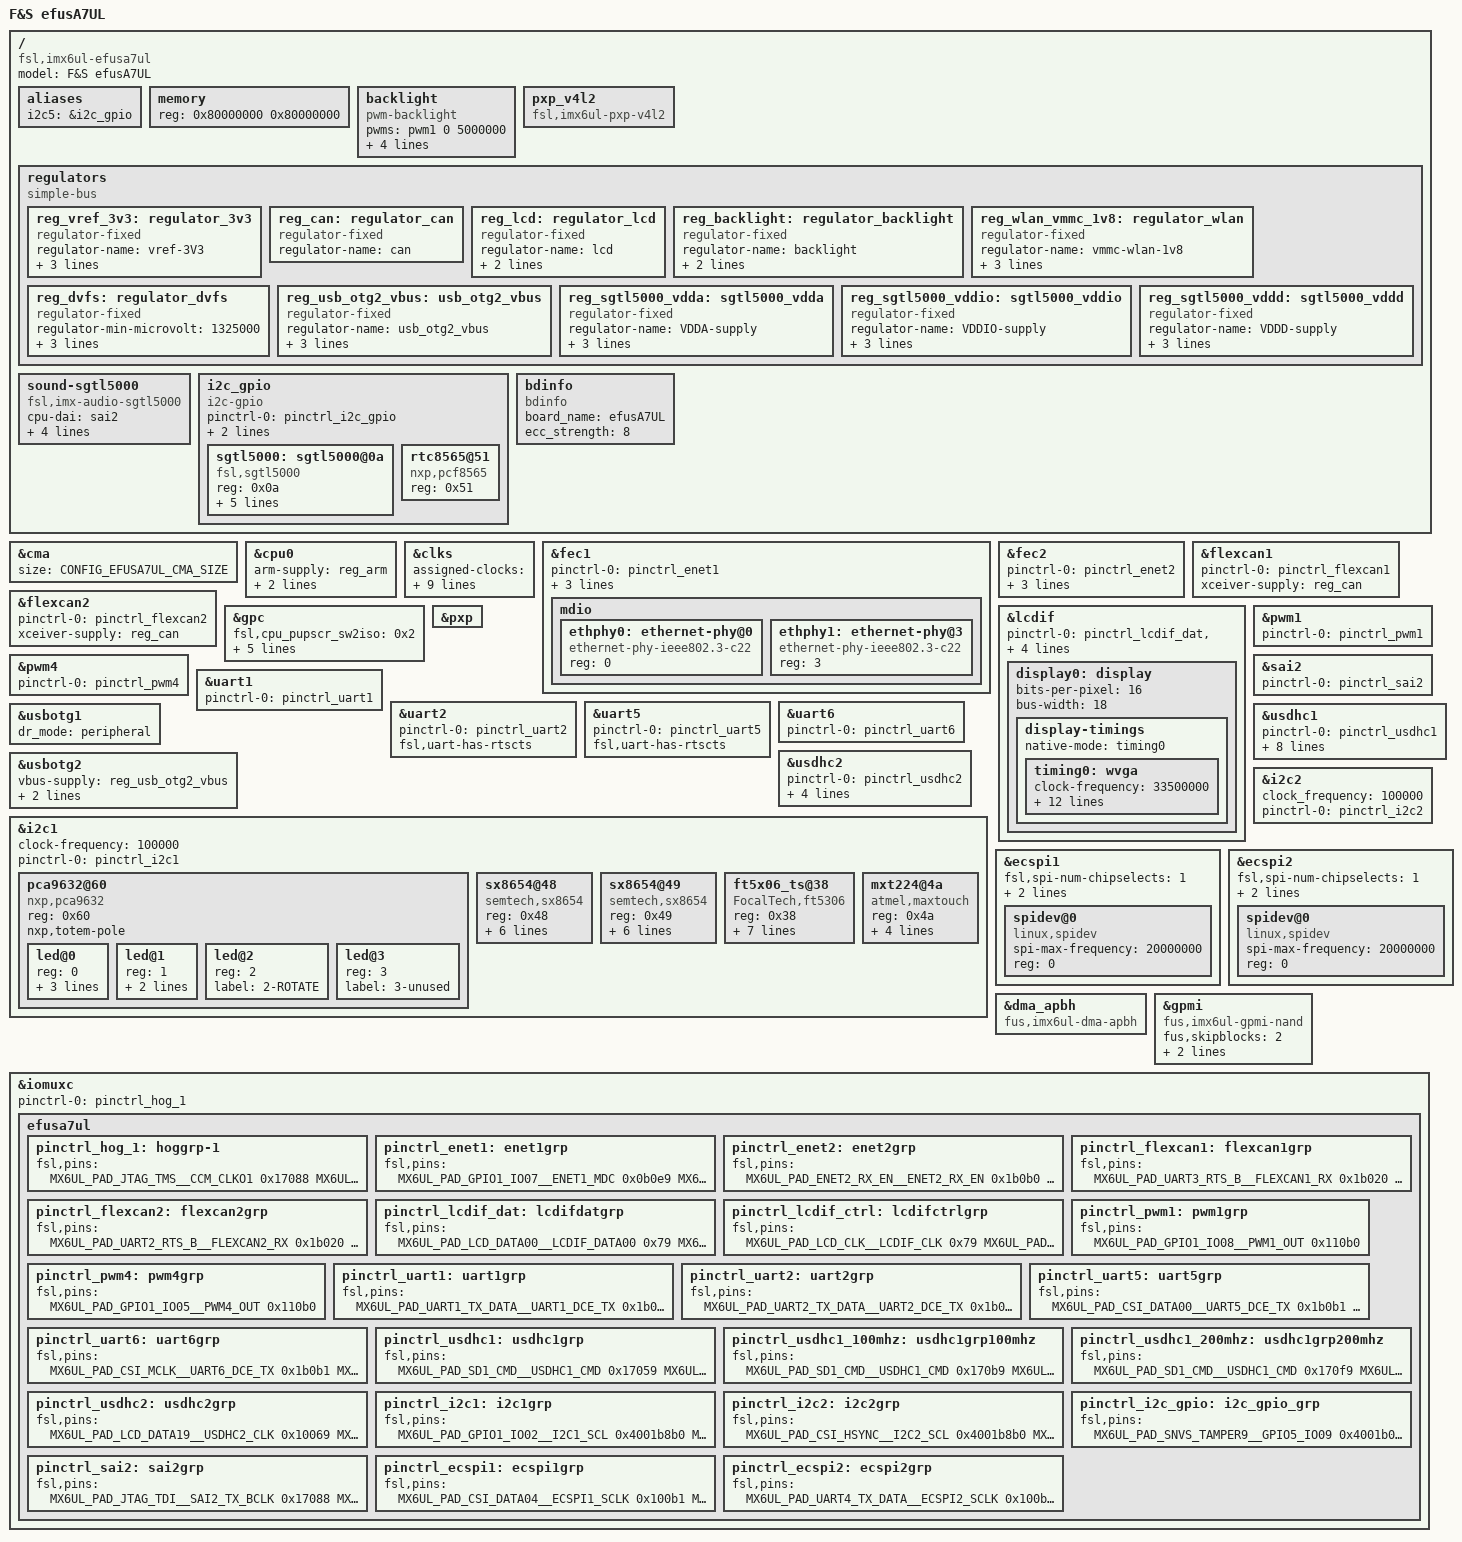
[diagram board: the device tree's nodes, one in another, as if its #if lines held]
/*
 * Copyright (C) 2015 Freescale Semiconductor, Inc.
 *
 * This program is free software; you can redistribute it and/or modify
 * it under the terms of the GNU General Public License version 2 as
 * published by the Free Software Foundation.
 */

#define CONFIG_EFUSA7UL_WLAN
#define CONFIG_EFUSA7UL_NAND
//#define CONFIG_EFUSA7UL_SD_A_CDWP

/* Please select only one of the following touch devices. Make sure that the
   corresponding touchscreen driver is activated in the kernel */
//#define CONFIG_EFUSA7UL_4WTOUCH_SX8655_ONBOARD
#define CONFIG_EFUSA7UL_4WTOUCH_SX8655_RGBADAPTER
//#define CONFIG_EFUSA7UL_CAPTOUCH_MXT224
//#define CONFIG_EFUSA7UL_CAPTOUCH_FT5x06

/* CMA: Set 64 MB for Continuous Memory Allocator */
#define CONFIG_EFUSA7UL_CMA_SIZE 0x4000000


/dts-v1/;

#include <dt-bindings/input/input.h>
#include "imx6ul.dtsi"

/ {
	model = "F&S efusA7UL";
	compatible = "fsl,imx6ul-efusa7ul", "fsl,imx6ul";

	aliases {
		i2c5 = &i2c_gpio;
	};
#if 0
	chosen {
		stdout-path = &uart1;
	};
#endif

	memory {
		reg = <0x80000000 0x80000000>;
	};

	backlight {
		compatible = "pwm-backlight";
		pwms = <&pwm1 0 5000000>;
		brightness-levels = <0 1 5 10 18 28 41 56
				     73 92 113 137 163 192 222 255>;
		default-brightness-level = <14>;
		power-supply = <&reg_backlight>;
		status = "okay";
	};

	pxp_v4l2 {
		compatible = "fsl,imx6ul-pxp-v4l2", "fsl,imx6sx-pxp-v4l2", "fsl,imx6sl-pxp-v4l2";
		status = "okay";
	};

	regulators {
		compatible = "simple-bus";
		#address-cells = <1>;
		#size-cells = <0>;

		reg_vref_3v3: regulator_3v3 {
			compatible = "regulator-fixed";
			regulator-name = "vref-3V3";
			regulator-min-microvolt = <3300000>;
			regulator-max-microvolt = <3300000>;
			regulator-always-on;
		};

		reg_can: regulator_can {
			compatible = "regulator-fixed";
			regulator-name = "can";
		};

		reg_lcd: regulator_lcd {
			compatible = "regulator-fixed";
			regulator-name = "lcd";
			gpio = <&gpio5 4 0>;
			enable-active-high;
		};

		reg_backlight: regulator_backlight {
			compatible = "regulator-fixed";
			regulator-name = "backlight";
			gpio = <&gpio5 5 0>;
			enable-active-high;
		};

#ifdef CONFIG_EFUSA7UL_WLAN
		reg_wlan_vmmc_1v8: regulator_wlan {
			compatible = "regulator-fixed";
			regulator-name = "vmmc-wlan-1v8";
			regulator-min-microvolt = <1800000>;
			regulator-max-microvolt = <1800000>;
			regulator-always-on;
		};
#endif

		reg_dvfs: regulator_dvfs {
			compatible = "regulator-fixed";
			regulator-min-microvolt = <1325000>;
			regulator-max-microvolt = <1325000>;
			regulator-name = "dvfs";
			regulator-always-on;
		};

		reg_usb_otg2_vbus: usb_otg2_vbus {
			compatible = "regulator-fixed";
			regulator-name = "usb_otg2_vbus";
			regulator-min-microvolt = <5000000>;
			regulator-max-microvolt = <5000000>;
			regulator-always-on;
		};

		/* SGTL5000 analog voltage */
		reg_sgtl5000_vdda: sgtl5000_vdda {
			compatible = "regulator-fixed";
			regulator-name = "VDDA-supply";
			regulator-min-microvolt = <3000000>;
			regulator-max-microvolt = <3000000>;
			regulator-always-on;
		};

		/* SGTL5000 I/O voltage */
		reg_sgtl5000_vddio: sgtl5000_vddio {
			compatible = "regulator-fixed";
			regulator-name = "VDDIO-supply";
			regulator-min-microvolt = <3300000>;
			regulator-max-microvolt = <3300000>;
			regulator-always-on;
		};

		/* SGTL5000 internal digital voltage */
		reg_sgtl5000_vddd: sgtl5000_vddd {
			compatible = "regulator-fixed";
			regulator-name = "VDDD-supply";
			regulator-min-microvolt = <1500000>;
			regulator-max-microvolt = <1500000>;
			regulator-always-on;
		};
	};

#if 1 //###
	sound-sgtl5000 {
		compatible = "fsl,imx-audio-sgtl5000";
		cpu-dai = <&sai2>;
		audio-codec = <&sgtl5000>;
		model = "imx-sgtl5000";
		audio-routing =
			"LINE_IN", "Line In Jack",
//###			"MIC_IN", "Mic Jack",
//###			"Line Out Jack", "LINE_OUT",
			"Headphone Jack", "HP_OUT";
	};
#endif

	/* Bitbanging I2C */
	i2c_gpio: i2c_gpio {
		pinctrl-names = "default";
		pinctrl-0 = <&pinctrl_i2c_gpio>;
		compatible = "i2c-gpio";
		gpios = <&gpio5 8 0 /* sda */
			 &gpio5 9 0 /* scl */
			>;
//###		i2c-gpio,sda-open-drain;
//###		i2c-gpio,scl-open-drain;
		i2c-gpio,delay-us = <2>;	/* ~100 kHz */
		#address-cells = <1>;
		#size-cells = <0>;
	};

	/* -------------------- BOARD INFO -------------------- */
	bdinfo {
		compatible = "bdinfo";
		board_name = "efusA7UL";
		ecc_strength = "8";
	};
};

/* RAM size for Continues Memory Allocator */
&cma {
	size = <CONFIG_EFUSA7UL_CMA_SIZE>;
};

&cpu0 {
	arm-supply = <&reg_arm>;
	soc-supply = <&reg_soc>;
	dc-supply = <&reg_dvfs>;
};

&clks {
	assigned-clocks = <&clks IMX6UL_CLK_PLL4_AUDIO_DIV>,
			  <&clks IMX6UL_CLK_SAI2_SEL>,
			  <&clks IMX6UL_CLK_SAI2>,
			  <&clks IMX6UL_CLK_CKO2_SEL>,
			  <&clks IMX6UL_CLK_CKO>;

	assigned-clock-parents = <0>,
				 <&clks IMX6UL_CLK_PLL4_AUDIO_DIV>,
				 <0>,
				 <&clks IMX6UL_CLK_SAI2>,
				 <&clks IMX6UL_CLK_CKO2>;
//###	assigned-clock-rates = <786432000>, <0>, <24576000>;
	assigned-clock-rates = <786432000>, <0>, <12288000>;
};

&fec1 {
	pinctrl-names = "default";
	pinctrl-0 = <&pinctrl_enet1>;
	phy-mode = "rmii";
	phy-handle = <&ethphy0>;
	fsl,ref-clock-out;
	status = "okay";

	mdio {
		#address-cells = <1>;
		#size-cells = <0>;

		ethphy0: ethernet-phy@0 {
			compatible = "ethernet-phy-ieee802.3-c22";
			reg = <0>;
		};

		ethphy1: ethernet-phy@3 {
			compatible = "ethernet-phy-ieee802.3-c22";
			reg = <3>;
		};
	};
};

&fec2 {
	pinctrl-names = "default";
	pinctrl-0 = <&pinctrl_enet2>;
	phy-mode = "rmii";
	phy-handle = <&ethphy1>;
	fsl,ref-clock-out;
//###	status = "okay";
};

&flexcan1 {
	pinctrl-names = "default";
	pinctrl-0 = <&pinctrl_flexcan1>;
	xceiver-supply = <&reg_can>;
	status = "okay";
};

&flexcan2 {
	pinctrl-names = "default";
	pinctrl-0 = <&pinctrl_flexcan2>;
	xceiver-supply = <&reg_can>;
	status = "okay";
};

&gpc {
	fsl,cpu_pupscr_sw2iso = <0x2>;
	fsl,cpu_pupscr_sw = <0x1>;
	fsl,cpu_pdnscr_iso2sw = <0x1>;
	fsl,cpu_pdnscr_iso = <0x1>;
	fsl,wdog-reset = <1>; /* watchdog select of reset source */
	fsl,ldo-bypass = <0>; /* DCDC, ldo-enable */
};

&lcdif {
	pinctrl-names = "default";
	pinctrl-0 = <&pinctrl_lcdif_dat
		     &pinctrl_lcdif_ctrl>;
	lcd-supply = <&reg_lcd>;
	display = <&display0>;
	/* efusA7UL Rev 1.00 needs 5, later revisions need 0 */
	pattern = <5>;		/* RGB=0, RBG=1, GBR=2, GRB=3, BRG=4, BGR=5 */
	status = "okay";

	display0: display {
		bits-per-pixel = <16>;
		bus-width = <18>;

		display-timings {
			native-mode = <&timing0>;
			timing0: wvga {
				clock-frequency = <33500000>;
				hactive = <800>;
				vactive = <480>;
				hfront-porch = <40>;
				hback-porch = <88>;
				hsync-len = <128>;
				vback-porch = <33>;
				vfront-porch =<10>;
				vsync-len = <2>;
				hsync-active = <0>;
				vsync-active = <0>;
				de-active = <1>;
				pixelclk-active = <0>;
			};
		};
	};
};

&pwm1 {
	pinctrl-names = "default";
	pinctrl-0 = <&pinctrl_pwm1>;
	status = "okay";
};

&pwm4 {
	pinctrl-names = "default";
	pinctrl-0 = <&pinctrl_pwm4>;
	status = "okay";
};

&pxp {
	status = "okay";
};

&sai2 {
	pinctrl-names = "default";
	pinctrl-0 = <&pinctrl_sai2>;
#if 0 //### already assigned in &clks above
	assigned-clocks = <&clks IMX6UL_CLK_SAI2_SEL>,
			  <&clks IMX6UL_CLK_SAI2>;
	assigned-clock-parents = <&clks IMX6UL_CLK_PLL4_AUDIO_DIV>;
//###	assigned-clock-rates = <0>, <12288000>;
	assigned-clock-rates = <0>, <24576000>;
#endif
	status = "okay";
};

/* UART_A */
&uart1 {
	pinctrl-names = "default";
	pinctrl-0 = <&pinctrl_uart1>;
	status = "okay";
};

/* UART_B */
&uart2 {
	pinctrl-names = "default";
	pinctrl-0 = <&pinctrl_uart2>;
	fsl,uart-has-rtscts;
	status = "okay";
};

/* UART_C or UART for Bluetooth */
&uart5 {
	pinctrl-names = "default";
	pinctrl-0 = <&pinctrl_uart5>;
	fsl,uart-has-rtscts;
	status = "okay";
};

/* UART_D */
&uart6 {
	pinctrl-names = "default";
	pinctrl-0 = <&pinctrl_uart6>;
	status = "okay";
};

&usbotg1 {
	dr_mode = "peripheral";
	status = "okay";
};

&usbotg2 {
	vbus-supply = <&reg_usb_otg2_vbus>;
	dr_mode = "host";
	disable-over-current;
	status = "okay";
};

/* Either on-board WLAN or SD_A (Micro-SD slot on SKIT) */
&usdhc1 {
	pinctrl-names = "default", "state_100mhz", "state_200mhz";
	pinctrl-0 = <&pinctrl_usdhc1>;
	pinctrl-1 = <&pinctrl_usdhc1_100mhz>;
	pinctrl-2 = <&pinctrl_usdhc1_200mhz>;
	bus-width = <4>;
	vmmc-supply = <&reg_vref_3v3>;
#ifdef CONFIG_EFUSA7UL_WLAN
	non-removable;
	keep-power-in-suspend;
	enable-sdio-wakeup;
	vqmmc-supply = <&reg_wlan_vmmc_1v8>;
#else
#ifdef CONFIG_EFUSA7UL_SD_A_CDWP
	cd-gpios = <&gpio1 19 GPIO_ACTIVE_LOW>;
	wp-gpios = <&gpio1 18 0>;
#else
	non-removable;
#endif
#endif
	status = "okay";
};

/* Either on-board eMMC or SD_B (normal sized SD slot on SKIT) */
&usdhc2 {
	pinctrl-names = "default";
	pinctrl-0 = <&pinctrl_usdhc2>;
	no-1-8-v;
#ifdef CONFIG_EFUSA7UL_NAND
	/* Only 4 data lines for SD_B or eMMC available */
	bus-width = <4>;
#else
	/* Use 8 data lines for eMMC */
	bus-width = <8>;
#endif
	/* ### TODO: set non-removable only if eMMC or board rev 1.00;
	   actually U-Boot should overwrite this property at boot time */
#ifdef CONFIG_EFUSA7UL_SD_A_CDWP
	non-removable;
#else
	cd-gpios = <&gpio1 19 GPIO_ACTIVE_LOW>;
	wp-gpios = <&gpio1 18 0>;
#endif
	vmmc-supply = <&reg_vref_3v3>;
	status = "okay";
};

/* I2C_A: RGB-Connector (SKIT -> SX8655, LED-driver PCA9632), Touch Connector
   (SKIT -> FT5x06, MXT), SX8655 (SKIT), Feature Connector (SKIT) */
&i2c1 {
	clock-frequency = <100000>;
	pinctrl-names = "default";
	pinctrl-0 = <&pinctrl_i2c1>;
	status = "okay";

	pca9632@60 {
		compatible = "nxp,pca9632";
		reg = <0x60>;
		nxp,totem-pole;
		#address-cells = <1>;
		#size-cells = <0>;
		led@0 {
			reg = <0>;
			label = "0-PWRCTL";
			default-on;
			active-high;
		};
		led@1 {
			reg = <1>;
			label = "1-LEDCTRL";
			default-on;
		};
		led@2 {
			reg = <2>;
			label = "2-ROTATE";
		};
		led@3 {
			reg = <3>;
			label = "3-unused";
		};
	};

#ifdef CONFIG_EFUSA7UL_4WTOUCH_SX8655_ONBOARD
	/* 4/5 wire analog resistive touch, controller on efus SKIT */
	sx8654@48 {
		compatible = "semtech,sx8654";
		reg = <0x48>;
		touchrate = <0x30>;
		powdly = <0x06>;
		filt = <0x02>;
		setdly = <0x08>;
		pinctrl-names = "default";
		/*pinctrl-0 = <&pinctrl_touchscreen>;*/
		interrupt-parent = <&gpio5>;
		interrupts = <0 IRQ_TYPE_EDGE_FALLING>;
	};
#endif

#ifdef CONFIG_EFUSA7UL_4WTOUCH_SX8655_RGBADAPTER
	/* 4/5 wire analog resistive touch, controller on RGB adapter */
	sx8654@49 {
		compatible = "semtech,sx8654";
		reg = <0x49>;
		touchrate = <0x30>;
		powdly = <0x06>;
		filt = <0x02>;
		setdly = <0x08>;
		pinctrl-names = "default";
		/*pinctrl-0 = <&pinctrl_touchscreen>;*/
		interrupt-parent = <&gpio5>;
		interrupts = <0 IRQ_TYPE_EDGE_FALLING>;
	};
#endif

#ifdef CONFIG_EFUSA7UL_CAPTOUCH_FT5x06
	/* F&S driver V3.0 on Touch-Connector (I2C) */
	ft5x06_ts@38 {
		compatible = "FocalTech,ft5306";
		reg = <0x38>;
		fingers = <2>;
		touchscreen-size-x = <800>;
		touchscreen-size-y = <480>;
		threshold = <25>;
		interrupt-parent = <&gpio5>;
		interrupts = <0 IRQ_TYPE_EDGE_FALLING>;
		linux,wakeup;
	};
#endif

#ifdef CONFIG_EFUSA7UL_CAPTOUCH_MXT224
	/* Atmel PCAP touch on Touch-Connector (I2C) */
	mxt224@4a {
		compatible = "atmel,maxtouch";
		reg = <0x4a>;
		interrupt-parent = <&gpio5>;
		interrupts = <0 2>;
		atmel,cfg_name = "atmel/mxt224.cfg";
		atmel,reset-gpio = <&gpio5 2 GPIO_ACTIVE_LOW>;
#if 0
		atmel,suspend-mode = <2>;
		vdd = <&reg_atmel_mxt_vdd>;
		avdd = <&reg_atmel_mxt_avdd>;
#endif
	};
#endif
};

/* I2C_B: Feature Connector (SKIT) */
&i2c2 {
	clock_frequency = <100000>;
	pinctrl-names = "default";
	pinctrl-0 = <&pinctrl_i2c2>;
	status = "okay";

	// ### TODO: FT5x06 on I2C_B

#if 0
	mxt224@4a {
		compatible = "atmel,maxtouch";
		reg = <0x4a>;
		interrupt-parent = <&gpio5>;
		interrupts = <1 2>;
		atmel,cfg_name = "mxt224.cfg";
		atmel,reset-gpio = <&gpio5 3 GPIO_ACTIVE_LOW>;
#if 0
		atmel,suspend-mode = <2>;
		vdd = <&reg_atmel_mxt_vdd>;
		avdd = <&reg_atmel_mxt_avdd>;
#endif
	};
#endif
};

/* I2C_C (Bitbanging): RTC (PCA8565), SGTL5000 (SKIT) */
&i2c_gpio {
	sgtl5000: sgtl5000@0a {
		compatible = "fsl,sgtl5000";
		reg = <0x0a>;
		//###clocks = <&clks IMX6UL_CLK_SAI2>;
		//###clocks = <&clks IMX6UL_CLK_PLL42>;
		mono2both;
		clocks = <&clks IMX6UL_CLK_CKO>;
		VDDA-supply = <&reg_sgtl5000_vdda>;
		VDDIO-supply = <&reg_sgtl5000_vddio>;
		VDDD-supply = <&reg_sgtl5000_vddd>;
#if 0 //### Already assigned in &clks above
		assigned-clocks = <&clks IMX6UL_CLK_CKO1_SEL>,
				  <&clks IMX6UL_CLK_PLL4_AUDIO_DIV>;
		assigned-clock-parents = <&clks IMX6UL_CLK_PLL4_AUDIO_DIV>;
		assigned-clock-rates = <0>, <24576000>;
#endif
	};

	rtc8565@51 {
		compatible = "nxp,pcf8565", "nxp,pcf8563";
		reg = <0x51>;
	};
};

/* SPI_A (1x CS) */
&ecspi1 {
	fsl,spi-num-chipselects = <1>;
	cs-gpios = <&gpio4 26 0>;
	pinctrl-names = "default";
	pinctrl-0 = <&pinctrl_ecspi1>;
	status = "okay";

	spidev@0 {
		#address-cells = <1>;
		#size-cells = <1>;
		compatible = "linux,spidev";
		spi-max-frequency = <20000000>;
		reg = <0>;
	};
};

/* SPI_B (1x CS) */
&ecspi2 {
	fsl,spi-num-chipselects = <1>;
	cs-gpios = <&gpio1 29 0>;
	pinctrl-names = "default";
	pinctrl-0 = <&pinctrl_ecspi2>;
	status = "okay";

	spidev@0 {
		#address-cells = <1>;
		#size-cells = <1>;
		compatible = "linux,spidev";
		spi-max-frequency = <20000000>;
		reg = <0>;
	};
};

#if 0 //### TODO
&qspi {
	pinctrl-names = "default";
	pinctrl-0 = <&pinctrl_qspi>;
	status = "okay";
	ddrsmp=<0>;

	flash0: n25q256a@0 {
		#address-cells = <1>;
		#size-cells = <1>;
		compatible = "micron,n25q256a";
		spi-max-frequency = <29000000>;
		spi-nor,ddr-quad-read-dummy = <6>;
		reg = <0>;
	};
};
#endif //###

&dma_apbh {
	/* Switch to F&S implementation of APBH DMA driver for GPMI (NAND) */
	compatible = "fus,imx6ul-dma-apbh", "fus,imx28-dma-apbh";
};

#ifdef CONFIG_EFUSA7UL_NAND
&gpmi {
	/* Switch to F&S implementation of GPMI NAND driver */
	compatible = "fus,imx6ul-gpmi-nand", "fus,imx6q-gpmi-nand";
	pinctrl-names = "default";
//###	pinctrl-0 = <&pinctrl_gpmi_nand_1>;
	fus,skipblocks = <2>;
	fus,chunk1k;
	fus,ecc_strength = <8>;
	status = "okay";
};
#endif

&iomuxc {
	pinctrl-names = "default";
	pinctrl-0 = <&pinctrl_hog_1>;
	efusa7ul {
		pinctrl_hog_1: hoggrp-1 {
			fsl,pins = <
/*###*/				MX6UL_PAD_JTAG_TMS__CCM_CLKO1		0x17088

				/* SD_A Card Detect (CD) pin */
				MX6UL_PAD_UART1_RTS_B__GPIO1_IO19	0x17059

				/* SD_A Write Protect (WP) pin */
				MX6UL_PAD_UART1_CTS_B__GPIO1_IO18	0x17059

				/* SD_A Reset (for eMMC) */
				MX6UL_PAD_GPIO1_IO09__GPIO1_IO09	0x17059

				/* I2C_A IRQ (ext. touch, etc.) */
				MX6UL_PAD_SNVS_TAMPER0__GPIO5_IO00	0x80000000

				/* I2C_A Reset (ext. touch, etc.) */
				MX6UL_PAD_SNVS_TAMPER2__GPIO5_IO02	0x80000000

				/* I2C_B IRQ (ext. touch, etc.) */
				MX6UL_PAD_SNVS_TAMPER1__GPIO5_IO01	0x80000000
				/* I2C_B Reset (ext. touch, etc.) */
				MX6UL_PAD_SNVS_TAMPER3__GPIO5_IO03	0x80000000

				/* VLCD */
				MX6UL_PAD_SNVS_TAMPER4__GPIO5_IO04	0x80000000
				/* VCFL */
				MX6UL_PAD_SNVS_TAMPER5__GPIO5_IO05	0x80000000
#if 0 //###
				MX6UL_PAD_LCD_RESET__WDOG1_WDOG_ANY	0x30b0
#endif
			>;
		};

		pinctrl_enet1: enet1grp {
			fsl,pins = <
				/* MDIO */
				MX6UL_PAD_GPIO1_IO07__ENET1_MDC		0x0b0e9
				MX6UL_PAD_GPIO1_IO06__ENET1_MDIO	0x0b831

				/* FEC0 */
				MX6UL_PAD_ENET1_RX_EN__ENET1_RX_EN	0x0b0e9
				MX6UL_PAD_ENET1_RX_ER__ENET1_RX_ER	0x0b0e9
				MX6UL_PAD_ENET1_RX_DATA0__ENET1_RDATA00	0x0b0e9
				MX6UL_PAD_ENET1_RX_DATA1__ENET1_RDATA01	0x0b0e9
				MX6UL_PAD_ENET1_TX_EN__ENET1_TX_EN	0x0b0e9
				MX6UL_PAD_ENET1_TX_DATA0__ENET1_TDATA00	0x0b0e9
				MX6UL_PAD_ENET1_TX_DATA1__ENET1_TDATA01	0x0b0e9
				MX6UL_PAD_ENET1_TX_CLK__ENET1_REF_CLK1	0x40000031

				/* PHY interrupt; on efusA7UL this is shared
				   on both PHYs and even the PCA8565 RTC uses
				   the same interrupt line! */
				MX6UL_PAD_LCD_RESET__GPIO3_IO04		0x80000000

				/* On efusA7UL, there is no specific PHY reset.
				   Reset is done by the global RESETOUTn signal
				   that we trigger in U-Boot already. */
			>;
		};

		pinctrl_enet2: enet2grp {
			fsl,pins = <
				MX6UL_PAD_ENET2_RX_EN__ENET2_RX_EN	0x1b0b0
				MX6UL_PAD_ENET2_RX_ER__ENET2_RX_ER	0x1b0b0
				MX6UL_PAD_ENET2_RX_DATA0__ENET2_RDATA00	0x1b0b0
				MX6UL_PAD_ENET2_RX_DATA1__ENET2_RDATA01	0x1b0b0
				MX6UL_PAD_ENET2_TX_EN__ENET2_TX_EN	0x1b0b0
				MX6UL_PAD_ENET2_TX_DATA0__ENET2_TDATA00	0x1b0b0
				MX6UL_PAD_ENET2_TX_DATA1__ENET2_TDATA01	0x1b0b0
				MX6UL_PAD_ENET2_TX_CLK__ENET2_REF_CLK2	0x4001b031
			>;
		};

		pinctrl_flexcan1: flexcan1grp{
			fsl,pins = <
				MX6UL_PAD_UART3_RTS_B__FLEXCAN1_RX	0x1b020
				MX6UL_PAD_UART3_CTS_B__FLEXCAN1_TX	0x1b020
			>;
		};

		pinctrl_flexcan2: flexcan2grp{
			fsl,pins = <
				MX6UL_PAD_UART2_RTS_B__FLEXCAN2_RX	0x1b020
				MX6UL_PAD_UART2_CTS_B__FLEXCAN2_TX	0x1b020
			>;
		};

		pinctrl_lcdif_dat: lcdifdatgrp {
			fsl,pins = <
				MX6UL_PAD_LCD_DATA00__LCDIF_DATA00	0x79
				MX6UL_PAD_LCD_DATA01__LCDIF_DATA01	0x79
				MX6UL_PAD_LCD_DATA02__LCDIF_DATA02	0x79
				MX6UL_PAD_LCD_DATA03__LCDIF_DATA03	0x79
				MX6UL_PAD_LCD_DATA04__LCDIF_DATA04	0x79
				MX6UL_PAD_LCD_DATA05__LCDIF_DATA05	0x79
				MX6UL_PAD_LCD_DATA06__LCDIF_DATA06	0x79
				MX6UL_PAD_LCD_DATA07__LCDIF_DATA07	0x79
				MX6UL_PAD_LCD_DATA08__LCDIF_DATA08	0x79
				MX6UL_PAD_LCD_DATA09__LCDIF_DATA09	0x79
				MX6UL_PAD_LCD_DATA10__LCDIF_DATA10	0x79
				MX6UL_PAD_LCD_DATA11__LCDIF_DATA11	0x79
				MX6UL_PAD_LCD_DATA12__LCDIF_DATA12	0x79
				MX6UL_PAD_LCD_DATA13__LCDIF_DATA13	0x79
				MX6UL_PAD_LCD_DATA14__LCDIF_DATA14	0x79
				MX6UL_PAD_LCD_DATA15__LCDIF_DATA15	0x79
				MX6UL_PAD_LCD_DATA16__LCDIF_DATA16	0x79
				MX6UL_PAD_LCD_DATA17__LCDIF_DATA17	0x79
			>;
		};

		pinctrl_lcdif_ctrl: lcdifctrlgrp {
			fsl,pins = <
				MX6UL_PAD_LCD_CLK__LCDIF_CLK		0x79
				MX6UL_PAD_LCD_ENABLE__LCDIF_ENABLE	0x79
				MX6UL_PAD_LCD_HSYNC__LCDIF_HSYNC	0x79
				MX6UL_PAD_LCD_VSYNC__LCDIF_VSYNC	0x79
			>;
		};

		pinctrl_pwm1: pwm1grp {
			fsl,pins = <
				MX6UL_PAD_GPIO1_IO08__PWM1_OUT		0x110b0
			>;
		};

		pinctrl_pwm4: pwm4grp {
			fsl,pins = <
				MX6UL_PAD_GPIO1_IO05__PWM4_OUT		0x110b0
			>;
		};

		pinctrl_uart1: uart1grp {
			fsl,pins = <
				MX6UL_PAD_UART1_TX_DATA__UART1_DCE_TX	0x1b0b1
				MX6UL_PAD_UART1_RX_DATA__UART1_DCE_RX	0x1b0b1
			>;
		};

		pinctrl_uart2: uart2grp {
			fsl,pins = <
				MX6UL_PAD_UART2_TX_DATA__UART2_DCE_TX	0x1b0b1
				MX6UL_PAD_UART2_RX_DATA__UART2_DCE_RX	0x1b0b1
				MX6UL_PAD_UART3_RX_DATA__UART2_DCE_RTS	0x1b0b1
				MX6UL_PAD_UART3_TX_DATA__UART2_DCE_CTS	0x1b0b1
			>;
		};

		pinctrl_uart5: uart5grp {
			fsl,pins = <
				MX6UL_PAD_CSI_DATA00__UART5_DCE_TX	0x1b0b1
				MX6UL_PAD_CSI_DATA01__UART5_DCE_RX	0x1b0b1
				MX6UL_PAD_CSI_DATA02__UART5_DCE_RTS	0x1b0b1
				MX6UL_PAD_CSI_DATA03__UART5_DCE_CTS	0x1b0b1
			>;
		};

		pinctrl_uart6: uart6grp {
			fsl,pins = <
				MX6UL_PAD_CSI_MCLK__UART6_DCE_TX	0x1b0b1
				MX6UL_PAD_CSI_PIXCLK__UART6_DCE_RX	0x1b0b1
			>;
		};

		pinctrl_usdhc1: usdhc1grp {
			fsl,pins = <
				MX6UL_PAD_SD1_CMD__USDHC1_CMD		0x17059
				MX6UL_PAD_SD1_CLK__USDHC1_CLK		0x10071
				MX6UL_PAD_SD1_DATA0__USDHC1_DATA0	0x17059
				MX6UL_PAD_SD1_DATA1__USDHC1_DATA1	0x17059
				MX6UL_PAD_SD1_DATA2__USDHC1_DATA2	0x17059
				MX6UL_PAD_SD1_DATA3__USDHC1_DATA3	0x17059
			>;
		};

		pinctrl_usdhc1_100mhz: usdhc1grp100mhz {
			fsl,pins = <
				MX6UL_PAD_SD1_CMD__USDHC1_CMD		0x170b9
				MX6UL_PAD_SD1_CLK__USDHC1_CLK		0x100b9
				MX6UL_PAD_SD1_DATA0__USDHC1_DATA0	0x170b9
				MX6UL_PAD_SD1_DATA1__USDHC1_DATA1	0x170b9
				MX6UL_PAD_SD1_DATA2__USDHC1_DATA2	0x170b9
				MX6UL_PAD_SD1_DATA3__USDHC1_DATA3	0x170b9
			>;
		};

		pinctrl_usdhc1_200mhz: usdhc1grp200mhz {
			fsl,pins = <
				MX6UL_PAD_SD1_CMD__USDHC1_CMD		0x170f9
				MX6UL_PAD_SD1_CLK__USDHC1_CLK		0x100f9
				MX6UL_PAD_SD1_DATA0__USDHC1_DATA0	0x170f9
				MX6UL_PAD_SD1_DATA1__USDHC1_DATA1	0x170f9
				MX6UL_PAD_SD1_DATA2__USDHC1_DATA2	0x170f9
				MX6UL_PAD_SD1_DATA3__USDHC1_DATA3	0x170f9
			>;
		};

		pinctrl_usdhc2: usdhc2grp {
			fsl,pins = <
				MX6UL_PAD_LCD_DATA19__USDHC2_CLK	0x10069
				MX6UL_PAD_LCD_DATA18__USDHC2_CMD	0x17059
				MX6UL_PAD_LCD_DATA20__USDHC2_DATA0	0x17059
				MX6UL_PAD_LCD_DATA21__USDHC2_DATA1	0x17059
				MX6UL_PAD_LCD_DATA22__USDHC2_DATA2	0x17059
				MX6UL_PAD_LCD_DATA23__USDHC2_DATA3	0x17059
#ifndef CONFIG_EFUSA7UL_NAND
				/* If no NAND, use 8 data lines on eMMC */
				MX6UL_PAD_NAND_DATA04__USDHC2_DATA4	0x17059
				MX6UL_PAD_NAND_DATA05__USDHC2_DATA5	0x17059
				MX6UL_PAD_NAND_DATA06__USDHC2_DATA6	0x17059
				MX6UL_PAD_NAND_DATA07__USDHC2_DATA7	0x17059
#endif
			>;
		};

		pinctrl_i2c1: i2c1grp {
			fsl,pins = <
				MX6UL_PAD_GPIO1_IO02__I2C1_SCL		0x4001b8b0
				MX6UL_PAD_GPIO1_IO03__I2C1_SDA		0x4001b8b0
			>;
		};

		pinctrl_i2c2: i2c2grp {
			fsl,pins = <
				MX6UL_PAD_CSI_HSYNC__I2C2_SCL		0x4001b8b0
				MX6UL_PAD_CSI_VSYNC__I2C2_SDA		0x4001b8b0
			>;
		};

		pinctrl_i2c_gpio: i2c_gpio_grp {
			fsl,pins = <
//###				MX6UL_PAD_SNVS_TAMPER9__GPIO5_IO09	0x4001b8b0
//###				MX6UL_PAD_SNVS_TAMPER8__GPIO5_IO08	0x4001b8b0
				MX6UL_PAD_SNVS_TAMPER9__GPIO5_IO09	0x4001b0b0
				MX6UL_PAD_SNVS_TAMPER8__GPIO5_IO08	0x4001b0b0
			>;
		};

#if 0 //### TODO
		pinctrl_qspi: qspigrp {
			fsl,pins = <
				MX6UL_PAD_NAND_WP_B__QSPI_A_SCLK	0x70a1
				MX6UL_PAD_NAND_READY_B__QSPI_A_DATA00	0x70a1
				MX6UL_PAD_NAND_CE0_B__QSPI_A_DATA01	0x70a1
				MX6UL_PAD_NAND_CE1_B__QSPI_A_DATA02	0x70a1
				MX6UL_PAD_NAND_CLE__QSPI_A_DATA03	0x70a1
				MX6UL_PAD_NAND_DQS__QSPI_A_SS0_B	0x70a1
			>;
		};
#endif

		pinctrl_sai2: sai2grp {
			fsl,pins = <
				MX6UL_PAD_JTAG_TDI__SAI2_TX_BCLK	0x17088
				MX6UL_PAD_JTAG_TDO__SAI2_TX_SYNC	0x17088
				MX6UL_PAD_JTAG_TRST_B__SAI2_TX_DATA	0x11088
				MX6UL_PAD_JTAG_TCK__SAI2_RX_DATA	0x11088
//###				MX6UL_PAD_JTAG_TMS__SAI2_MCLK		0x17088
//###				MX6UL_PAD_JTAG_TMS__CCM_CLKO1		0x17088
//###				MX6UL_PAD_JTAG_TMS__GPIO1_IO11		0x80000000
			>;
		};

		pinctrl_ecspi1: ecspi1grp {
			fsl,pins = <
				MX6UL_PAD_CSI_DATA04__ECSPI1_SCLK	0x100b1
				MX6UL_PAD_CSI_DATA05__GPIO4_IO26	0x80000000
				MX6UL_PAD_CSI_DATA06__ECSPI1_MOSI	0x100b1
				MX6UL_PAD_CSI_DATA07__ECSPI1_MISO	0x100b1

				/* IRQ */
				MX6UL_PAD_SNVS_TAMPER6__GPIO5_IO06	0x80000000
			>;
		};

		pinctrl_ecspi2: ecspi2grp {
			fsl,pins = <
				MX6UL_PAD_UART4_TX_DATA__ECSPI2_SCLK	0x100b1
				MX6UL_PAD_UART4_RX_DATA__GPIO1_IO29	0x80000000
				MX6UL_PAD_UART5_TX_DATA__ECSPI2_MOSI	0x100b1
				MX6UL_PAD_UART5_RX_DATA__ECSPI2_MISO	0x100b1

				/* IRQ */
				MX6UL_PAD_SNVS_TAMPER7__GPIO5_IO07	0x80000000
			>;
		};

#ifdef CONFIG_EFUSA7UL_NAND
#if 0
		pinctrl_gpmi_nand_1: gpmi-nand-1 {
			/* Already configured in NBoot/U-Boot */
			fsl,pins = <
				MX6SX_PAD_NAND_CLE__RAWNAND_CLE		0xb0b1
				MX6SX_PAD_NAND_ALE__RAWNAND_ALE		0xb0b1
				MX6SX_PAD_NAND_WP_B__RAWNAND_WP_B	0xb0b1
				MX6SX_PAD_NAND_READY_B__RAWNAND_READY_B	0xb000
				MX6SX_PAD_NAND_CE0_B__RAWNAND_CE0_B	0xb0b1
				//MX6SX_PAD_NAND_CE1_B__RAWNAND_CE1_B	0xb0b1
				MX6SX_PAD_NAND_RE_B__RAWNAND_RE_B	0xb0b1
				MX6SX_PAD_NAND_WE_B__RAWNAND_WE_B	0xb0b1
				MX6SX_PAD_NAND_DATA00__RAWNAND_DATA00	0xb0b1
				MX6SX_PAD_NAND_DATA01__RAWNAND_DATA01	0xb0b1
				MX6SX_PAD_NAND_DATA02__RAWNAND_DATA02	0xb0b1
				MX6SX_PAD_NAND_DATA03__RAWNAND_DATA03	0xb0b1
				MX6SX_PAD_NAND_DATA04__RAWNAND_DATA04	0xb0b1
				MX6SX_PAD_NAND_DATA05__RAWNAND_DATA05	0xb0b1
				MX6SX_PAD_NAND_DATA06__RAWNAND_DATA06	0xb0b1
				MX6SX_PAD_NAND_DATA07__RAWNAND_DATA07	0xb0b1
			>;
		};
#endif
#endif
	};
};
